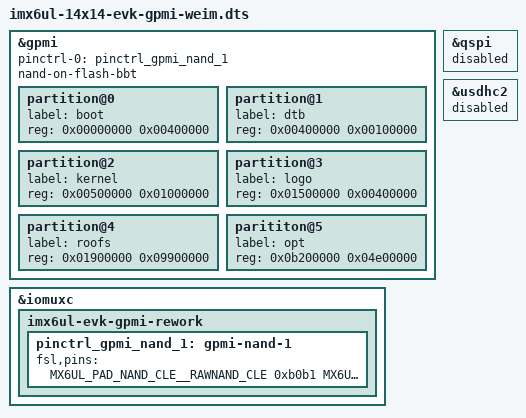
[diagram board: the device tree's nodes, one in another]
/*
 * Copyright (C) 2015 Freescale Semiconductor, Inc.
 *
 * This program is free software; you can redistribute it and/or modify
 * it under the terms of the GNU General Public License version 2 as
 * published by the Free Software Foundation.
 */

#include "imx6ul-14x14-evk.dts"

&gpmi {
	pinctrl-names = "default";
	pinctrl-0 = <&pinctrl_gpmi_nand_1>;
	status = "okay";
	nand-on-flash-bbt;
/*
        partition@0 {
                label = "boot";
                reg = <0x00000000 0x04000000>;
        };

        partition@1 {
                label = "kernel";
                reg = <0x04000000 0x01000000>;
        };

        partition@2 {
                label = "dtb";
                reg = <0x05000000 0x01000000>;
        };
//256M

        partition@3 {
                label = "roofs";
                reg = <0x06000000 0x0A000000>;
        };	


//512M

        partition@3 {
                label = "roofs";
                reg = <0x06000000 0x1A000000>;
        };      
*/


        partition@0 {
                label = "boot";
                reg = <0x00000000 0x00400000>;
        };

        partition@1 {
                label = "dtb";
                reg = <0x00400000 0x00100000>;
        };

        partition@2 {
                label = "kernel";
                reg = <0x00500000 0x01000000>;
        };

        partition@3 {                           
                label = "logo";
                reg = <0x01500000 0x00400000>;
        };

        partition@4 {                              
                label = "roofs";
                reg = <0x01900000 0x09900000>;
        };

        parititon@5 {
                label = "opt";
                reg = <0x0b200000 0x04e00000>;
        };

};

&iomuxc {
	imx6ul-evk-gpmi-rework {
		pinctrl_gpmi_nand_1: gpmi-nand-1 {
			fsl,pins = <
				MX6UL_PAD_NAND_CLE__RAWNAND_CLE         0xb0b1
				MX6UL_PAD_NAND_ALE__RAWNAND_ALE         0xb0b1
				MX6UL_PAD_NAND_WP_B__RAWNAND_WP_B       0xb0b1
				MX6UL_PAD_NAND_READY_B__RAWNAND_READY_B 0xb000
				MX6UL_PAD_NAND_CE0_B__RAWNAND_CE0_B     0xb0b1
				MX6UL_PAD_NAND_CE1_B__RAWNAND_CE1_B     0xb0b1
				MX6UL_PAD_NAND_RE_B__RAWNAND_RE_B       0xb0b1
				MX6UL_PAD_NAND_WE_B__RAWNAND_WE_B       0xb0b1
				MX6UL_PAD_NAND_DATA00__RAWNAND_DATA00   0xb0b1
				MX6UL_PAD_NAND_DATA01__RAWNAND_DATA01   0xb0b1
				MX6UL_PAD_NAND_DATA02__RAWNAND_DATA02   0xb0b1
				MX6UL_PAD_NAND_DATA03__RAWNAND_DATA03   0xb0b1
				MX6UL_PAD_NAND_DATA04__RAWNAND_DATA04   0xb0b1
				MX6UL_PAD_NAND_DATA05__RAWNAND_DATA05   0xb0b1
				MX6UL_PAD_NAND_DATA06__RAWNAND_DATA06   0xb0b1
				MX6UL_PAD_NAND_DATA07__RAWNAND_DATA07   0xb0b1
			>;
		};
	};
};

&qspi {
	status = "disabled";
};

&usdhc2 {
	status = "disabled";
};
